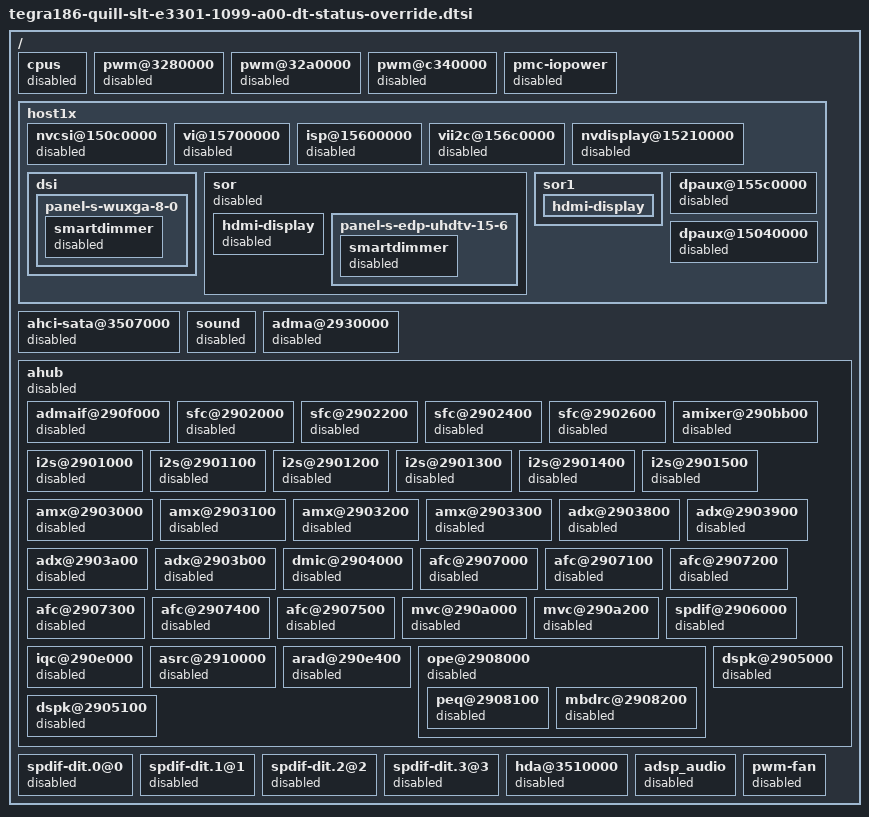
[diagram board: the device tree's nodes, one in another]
/*
 * tegra186-quill-slt-e3301-1099-a00-dt-status-override.dtsi:
 *
 * Copyright (c) 2015, NVIDIA CORPORATION.  All rights reserved.
 *
 * This program is free software; you can redistribute it and/or modify
 * it under the terms of the GNU General Public License as published by
 * the Free Software Foundation; version 2 of the License.
 *
 * This program is distributed in the hope that it will be useful, but WITHOUT
 * ANY WARRANTY; without even the implied warranty of MERCHANTABILITY or
 * FITNESS FOR A PARTICULAR PURPOSE.  See the GNU General Public License for
 * more details.
 */

/ {

	cpus {
		status = "disabled";
	};

	pwm@3280000 {
		status = "disabled";
	};

	pwm@32a0000 {
		status = "disabled";
	};

	pwm@c340000 {
		status = "disabled";
	};


	pmc-iopower {
		status = "disabled";
	};

	host1x {

		nvcsi@150c0000 {
			status = "disabled";
		};
		vi@15700000 {
			status = "disabled";
		};

		isp@15600000 {
			status = "disabled";
		};

		vii2c@156c0000 {
			status = "disabled";
		};

		nvdisplay@15210000 {
			status = "disabled";
		};

		dsi {
			panel-s-wuxga-8-0 {
				smartdimmer {
					status = "disabled";
				};
			};
		};

		sor {
			status = "disabled";
			hdmi-display {
				status = "disabled";
			};

			panel-s-edp-uhdtv-15-6 {
				smartdimmer {
					status = "disabled";
				};
			};
		};

		sor1 {
			hdmi-display {
				status = "okay";
			};
		};

		dpaux@155c0000 {
			status = "disabled";
		};
		dpaux@15040000 {
			status = "disabled";
		};
	};

	ahci-sata@3507000 {
		status = "disabled";
	};

	sound {
		status = "disabled";
	};

	adma@2930000 {
		status = "disabled";
	};

	ahub {
		status = "disabled";

		admaif@290f000 {
			status = "disabled";
		};

		sfc@2902000 {
			status = "disabled";
		};

		sfc@2902200 {
			status = "disabled";
		};

		sfc@2902400 {
			status = "disabled";
		};

		sfc@2902600 {
			status = "disabled";
		};

		amixer@290bb00 {
			status = "disabled";
		};

		i2s@2901000 {
			status = "disabled";
		};

		i2s@2901100 {
			status = "disabled";
		};

		i2s@2901200 {
			status = "disabled";
		};

		i2s@2901300 {
			status = "disabled";
		};

		i2s@2901400 {
			status = "disabled";
		};

		i2s@2901500 {
			status = "disabled";
		};

		amx@2903000 {
			status = "disabled";
		};

		amx@2903100 {
			status = "disabled";
		};

		amx@2903200 {
			status = "disabled";
		};

		amx@2903300 {
			status = "disabled";
		};

		adx@2903800 {
			status = "disabled";
		};

		adx@2903900 {
			status = "disabled";
		};

		adx@2903a00 {
			status = "disabled";
		};

		adx@2903b00 {
			status = "disabled";
		};

		dmic@2904000 {
			status = "disabled";
		};

		afc@2907000 {
			status = "disabled";
		};

		afc@2907100 {
			status = "disabled";
		};

		afc@2907200 {
			status = "disabled";
		};

		afc@2907300 {
			status = "disabled";
		};

		afc@2907400 {
			status = "disabled";
		};

		afc@2907500 {
			status = "disabled";
		};

		mvc@290a000 {
			status = "disabled";
		};

		mvc@290a200 {
			status = "disabled";
		};

		spdif@2906000 {
			status = "disabled";
		};

		iqc@290e000 {
			status = "disabled";
		};

		asrc@2910000 {
			status = "disabled";
		};

		arad@290e400 {
			status = "disabled";
		};

		ope@2908000 {
			status = "disabled";

			peq@2908100 {
				status = "disabled";
			};

			mbdrc@2908200 {
				status = "disabled";
			};
		};

		dspk@2905000 {
			status = "disabled";
		};

		dspk@2905100 {
			status = "disabled";
		};
	};

	spdif-dit.0@0 {
		status = "disabled";
	};

	spdif-dit.1@1 {
		status = "disabled";
	};

	spdif-dit.2@2 {
		status = "disabled";
	};

	spdif-dit.3@3 {
		status = "disabled";
	};
	hda@3510000 {
		status = "disabled";
	};

	adsp_audio {
		status = "disabled";
	};

	pwm-fan {
		status = "disabled";
	};
};

